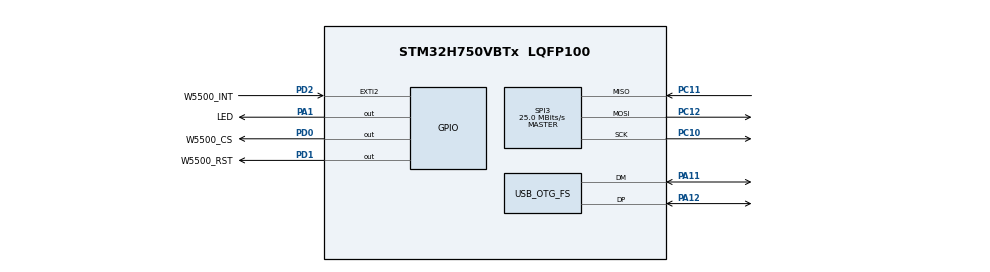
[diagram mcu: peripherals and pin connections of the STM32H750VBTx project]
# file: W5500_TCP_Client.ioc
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Mcu.Family=STM32H7
Mcu.Name=STM32H750VBTx
Mcu.Package=LQFP100
NVIC.EXTI2_IRQn=true\:0\:0\:false\:false\:true\:true\:true\:true
NVIC.OTG_FS_IRQn=true\:0\:0\:false\:false\:true\:false\:true\:true
NVIC.PriorityGroup=NVIC_PRIORITYGROUP_4
NVIC.TIM17_IRQn=true\:15\:0\:false\:false\:true\:false\:true\:true
NVIC.TimeBase=TIM17_IRQn
NVIC.TimeBaseIP=TIM17
PA1.GPIO_Label=LED
PA1.PinState=GPIO_PIN_SET
PA1.Signal=GPIO_Output
PA11.Mode=Device_Only
PA11.Signal=USB_OTG_FS_DM
PA12.Mode=Device_Only
PA12.Signal=USB_OTG_FS_DP
PA13\ (JTMS/SWDIO).Mode=Serial_Wire
PA13\ (JTMS/SWDIO).Signal=DEBUG_JTMS-SWDIO
PA14\ (JTCK/SWCLK).Mode=Serial_Wire
PA14\ (JTCK/SWCLK).Signal=DEBUG_JTCK-SWCLK
PC10.Mode=Full_Duplex_Master
PC10.Signal=SPI3_SCK
PC11.Mode=Full_Duplex_Master
PC11.Signal=SPI3_MISO
PC12.Mode=Full_Duplex_Master
PC12.Signal=SPI3_MOSI
PD0.GPIO_Label=W5500_CS
PD0.GPIO_ModeDefaultOutputPP=GPIO_MODE_OUTPUT_PP
PD0.GPIO_PuPd=GPIO_PULLUP
PD0.PinState=GPIO_PIN_SET
PD0.Signal=GPIO_Output
PD1.GPIO_Label=W5500_RST
PD1.GPIO_ModeDefaultOutputPP=GPIO_MODE_OUTPUT_PP
PD1.GPIO_PuPd=GPIO_PULLUP
PD1.PinState=GPIO_PIN_SET
PD1.Signal=GPIO_Output
PD2.GPIO_Label=W5500_INT
PD2.GPIO_ModeDefaultEXTI=GPIO_MODE_IT_FALLING
PD2.GPIO_PuPd=GPIO_PULLUP
PD2.Signal=GPXTI2
PH0-OSC_IN\ (PH0).Mode=HSE-External-Oscillator
PH0-OSC_IN\ (PH0).Signal=RCC_OSC_IN
PH1-OSC_OUT\ (PH1).Mode=HSE-External-Oscillator
PH1-OSC_OUT\ (PH1).Signal=RCC_OSC_OUT
ProjectManager.HeapSize=0x200
ProjectManager.StackSize=0x400
ProjectManager.TargetToolchain=STM32CubeIDE
RCC.ADCFreq_Value=50390625
RCC.APB1Freq_Value=100000000
RCC.APB2Freq_Value=100000000
RCC.APB3Freq_Value=100000000
RCC.APB4Freq_Value=100000000
RCC.CortexFreq_Value=200000000
RCC.D1PPRE=RCC_APB3_DIV2
RCC.D2PPRE1=RCC_APB1_DIV2
RCC.D2PPRE2=RCC_APB2_DIV2
RCC.D3PPRE=RCC_APB4_DIV2
RCC.DIVM1=2
RCC.DIVN1=32
RCC.DIVQ1=4
RCC.HCLKFreq_Value=200000000
RCC.PLLFRACN=0
RCC.PLLSourceVirtual=RCC_PLLSOURCE_HSE
RCC.SYSCLKFreq_VALUE=200000000
RCC.SYSCLKSource=RCC_SYSCLKSOURCE_PLLCLK
RCC.USBCLockSelection=RCC_USBCLKSOURCE_HSI48
RCC.USBFreq_Value=48000000
SPI3.BaudRatePrescaler=SPI_BAUDRATEPRESCALER_4
SPI3.CalculateBaudRate=25.0 MBits/s
SPI3.DataSize=SPI_DATASIZE_8BIT
SPI3.Direction=SPI_DIRECTION_2LINES
SPI3.Mode=SPI_MODE_MASTER
SPI3.VirtualType=VM_MASTER
USB_DEVICE.CLASS_NAME_FS=CDC
USB_DEVICE.VirtualMode-CDC_FS=Cdc
USB_DEVICE.VirtualModeFS=Cdc_FS
USB_OTG_FS.VirtualMode=Device_Only
VP_SYS_VS_tim17.Mode=TIM17
VP_USB_DEVICE_VS_USB_DEVICE_CDC_FS.Mode=CDC_FS
board=custom

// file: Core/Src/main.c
/* USER CODE BEGIN Header */
/**
  ******************************************************************************
  * @file           : main.c
  * @brief          : Main program body
  ******************************************************************************
  * @attention
  *
  * Copyright (c) 2023 STMicroelectronics.
  * All rights reserved.
  *
  * This software is licensed under terms that can be found in the LICENSE file
  * in the root directory of this software component.
  * If no LICENSE file comes with this software, it is provided AS-IS.
  *
  ******************************************************************************
  */
/* USER CODE END Header */
#include "main.h"
#include "usb_device.h"

/* USER CODE BEGIN Includes */
#include<stdio.h>
#include<stdlib.h>

/* USER CODE END Includes */

SPI_HandleTypeDef hspi3;

void SystemClock_Config(void);
static void MX_GPIO_Init(void);
static void MX_SPI3_Init(void);

int main(void)
{

  /* MCU Configuration--------------------------------------------------------*/

  /* Reset of all peripherals, Initializes the Flash interface and the Systick. */
  HAL_Init();

  /* Configure the system clock */
  SystemClock_Config();

  /* Initialize all configured peripherals */
  MX_GPIO_Init();
  MX_SPI3_Init();
  MX_USB_DEVICE_Init();
  /* USER CODE BEGIN 2 */
	setup();
  /* USER CODE END 2 */

  /* Infinite loop */
  while (1)
  {

    /* USER CODE BEGIN 3 */
	loop();
  }
  /* USER CODE END 3 */
}

void SystemClock_Config(void)
{
  RCC_OscInitTypeDef RCC_OscInitStruct = {0};
  RCC_ClkInitTypeDef RCC_ClkInitStruct = {0};

  /** Supply configuration update enable
  */
  HAL_PWREx_ConfigSupply(PWR_LDO_SUPPLY);

  /** Configure the main internal regulator output voltage
  */
  __HAL_PWR_VOLTAGESCALING_CONFIG(PWR_REGULATOR_VOLTAGE_SCALE3);

  while(!__HAL_PWR_GET_FLAG(PWR_FLAG_VOSRDY)) {}

  /** Initializes the RCC Oscillators according to the specified parameters
  * in the RCC_OscInitTypeDef structure.
  */
  RCC_OscInitStruct.OscillatorType = RCC_OSCILLATORTYPE_HSI48|RCC_OSCILLATORTYPE_HSE;
  RCC_OscInitStruct.HSEState = RCC_HSE_ON;
  RCC_OscInitStruct.HSI48State = RCC_HSI48_ON;
  RCC_OscInitStruct.PLL.PLLState = RCC_PLL_ON;
  RCC_OscInitStruct.PLL.PLLSource = RCC_PLLSOURCE_HSE;
  RCC_OscInitStruct.PLL.PLLM = 2;
  RCC_OscInitStruct.PLL.PLLN = 32;
  RCC_OscInitStruct.PLL.PLLP = 2;
  RCC_OscInitStruct.PLL.PLLQ = 4;
  RCC_OscInitStruct.PLL.PLLR = 2;
  RCC_OscInitStruct.PLL.PLLRGE = RCC_PLL1VCIRANGE_3;
  RCC_OscInitStruct.PLL.PLLVCOSEL = RCC_PLL1VCOWIDE;
  RCC_OscInitStruct.PLL.PLLFRACN = 0;
  if (HAL_RCC_OscConfig(&RCC_OscInitStruct) != HAL_OK)
  {
    Error_Handler();
  }

  /** Initializes the CPU, AHB and APB buses clocks
  */
  RCC_ClkInitStruct.ClockType = RCC_CLOCKTYPE_HCLK|RCC_CLOCKTYPE_SYSCLK
                              |RCC_CLOCKTYPE_PCLK1|RCC_CLOCKTYPE_PCLK2
                              |RCC_CLOCKTYPE_D3PCLK1|RCC_CLOCKTYPE_D1PCLK1;
  RCC_ClkInitStruct.SYSCLKSource = RCC_SYSCLKSOURCE_PLLCLK;
  RCC_ClkInitStruct.SYSCLKDivider = RCC_SYSCLK_DIV1;
  RCC_ClkInitStruct.AHBCLKDivider = RCC_HCLK_DIV1;
  RCC_ClkInitStruct.APB3CLKDivider = RCC_APB3_DIV2;
  RCC_ClkInitStruct.APB1CLKDivider = RCC_APB1_DIV2;
  RCC_ClkInitStruct.APB2CLKDivider = RCC_APB2_DIV2;
  RCC_ClkInitStruct.APB4CLKDivider = RCC_APB4_DIV2;

  if (HAL_RCC_ClockConfig(&RCC_ClkInitStruct, FLASH_LATENCY_4) != HAL_OK)
  {
    Error_Handler();
  }
}

static void MX_SPI3_Init(void)
{

  /* SPI3 parameter configuration*/
  hspi3.Instance = SPI3;
  hspi3.Init.Mode = SPI_MODE_MASTER;
  hspi3.Init.Direction = SPI_DIRECTION_2LINES;
  hspi3.Init.DataSize = SPI_DATASIZE_8BIT;
  hspi3.Init.CLKPolarity = SPI_POLARITY_LOW;
  hspi3.Init.CLKPhase = SPI_PHASE_1EDGE;
  hspi3.Init.NSS = SPI_NSS_SOFT;
  hspi3.Init.BaudRatePrescaler = SPI_BAUDRATEPRESCALER_4;
  hspi3.Init.FirstBit = SPI_FIRSTBIT_MSB;
  hspi3.Init.TIMode = SPI_TIMODE_DISABLE;
  hspi3.Init.CRCCalculation = SPI_CRCCALCULATION_DISABLE;
  hspi3.Init.CRCPolynomial = 0x0;
  hspi3.Init.NSSPMode = SPI_NSS_PULSE_ENABLE;
  hspi3.Init.NSSPolarity = SPI_NSS_POLARITY_LOW;
  hspi3.Init.FifoThreshold = SPI_FIFO_THRESHOLD_01DATA;
  hspi3.Init.TxCRCInitializationPattern = SPI_CRC_INITIALIZATION_ALL_ZERO_PATTERN;
  hspi3.Init.RxCRCInitializationPattern = SPI_CRC_INITIALIZATION_ALL_ZERO_PATTERN;
  hspi3.Init.MasterSSIdleness = SPI_MASTER_SS_IDLENESS_00CYCLE;
  hspi3.Init.MasterInterDataIdleness = SPI_MASTER_INTERDATA_IDLENESS_00CYCLE;
  hspi3.Init.MasterReceiverAutoSusp = SPI_MASTER_RX_AUTOSUSP_DISABLE;
  hspi3.Init.MasterKeepIOState = SPI_MASTER_KEEP_IO_STATE_DISABLE;
  hspi3.Init.IOSwap = SPI_IO_SWAP_DISABLE;
  if (HAL_SPI_Init(&hspi3) != HAL_OK)
  {
    Error_Handler();
  }

}

static void MX_GPIO_Init(void)
{
  GPIO_InitTypeDef GPIO_InitStruct = {0};

  /* GPIO Ports Clock Enable */
  __HAL_RCC_GPIOH_CLK_ENABLE();
  __HAL_RCC_GPIOA_CLK_ENABLE();
  __HAL_RCC_GPIOC_CLK_ENABLE();
  __HAL_RCC_GPIOD_CLK_ENABLE();

  /*Configure GPIO pin Output Level */
  HAL_GPIO_WritePin(LED_GPIO_Port, LED_Pin, GPIO_PIN_SET);

  /*Configure GPIO pin Output Level */
  HAL_GPIO_WritePin(GPIOD, W5500_CS_Pin|W5500_RST_Pin, GPIO_PIN_SET);

  /*Configure GPIO pin : LED_Pin */
  GPIO_InitStruct.Pin = LED_Pin;
  GPIO_InitStruct.Mode = GPIO_MODE_OUTPUT_PP;
  GPIO_InitStruct.Pull = GPIO_NOPULL;
  GPIO_InitStruct.Speed = GPIO_SPEED_FREQ_LOW;
  HAL_GPIO_Init(LED_GPIO_Port, &GPIO_InitStruct);

  /*Configure GPIO pins : W5500_CS_Pin W5500_RST_Pin */
  GPIO_InitStruct.Pin = W5500_CS_Pin|W5500_RST_Pin;
  GPIO_InitStruct.Mode = GPIO_MODE_OUTPUT_PP;
  GPIO_InitStruct.Pull = GPIO_PULLUP;
  GPIO_InitStruct.Speed = GPIO_SPEED_FREQ_LOW;
  HAL_GPIO_Init(GPIOD, &GPIO_InitStruct);

  /*Configure GPIO pin : W5500_INT_Pin */
  GPIO_InitStruct.Pin = W5500_INT_Pin;
  GPIO_InitStruct.Mode = GPIO_MODE_IT_FALLING;
  GPIO_InitStruct.Pull = GPIO_PULLUP;
  HAL_GPIO_Init(W5500_INT_GPIO_Port, &GPIO_InitStruct);

  /* EXTI interrupt init*/
  HAL_NVIC_SetPriority(EXTI2_IRQn, 0, 0);
  HAL_NVIC_EnableIRQ(EXTI2_IRQn);

}

void HAL_TIM_PeriodElapsedCallback(TIM_HandleTypeDef *htim)
{
  if (htim->Instance == TIM17) {
    HAL_IncTick();
  }
}

void Error_Handler(void)
{
  __disable_irq();
  while (1)
  {
  }
}
